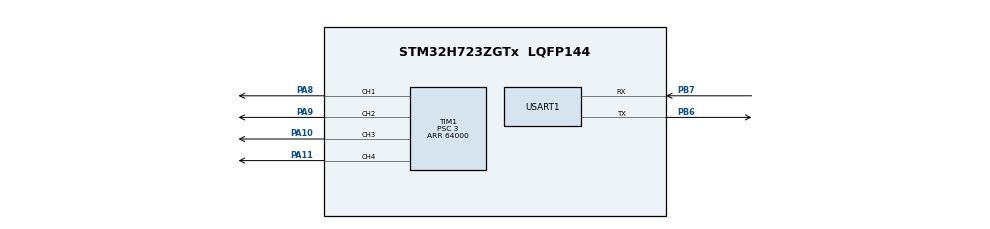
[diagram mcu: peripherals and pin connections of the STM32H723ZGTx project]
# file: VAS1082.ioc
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CORTEX_M7.CPU_DCache=Disabled
CORTEX_M7.CPU_ICache=Disabled
CORTEX_M7.default_mode_Activation=1
Mcu.Family=STM32H7
Mcu.Name=STM32H723ZGTx
Mcu.Package=LQFP144
NVIC.PriorityGroup=NVIC_PRIORITYGROUP_4
NVIC.TIM2_IRQn=true\:2\:0\:true\:false\:true\:true\:true\:true
NVIC.TIM3_IRQn=true\:1\:0\:true\:false\:true\:true\:true\:true
NVIC.TIM4_IRQn=true\:0\:0\:true\:false\:true\:true\:true\:true
NVIC.USART1_IRQn=true\:6\:0\:true\:false\:true\:true\:true\:true
PA10.Signal=S_TIM1_CH3
PA11.Signal=S_TIM1_CH4
PA13(JTMS/SWDIO).Mode=Serial_Wire
PA13(JTMS/SWDIO).Signal=DEBUG_JTMS-SWDIO
PA14(JTCK/SWCLK).Mode=Serial_Wire
PA14(JTCK/SWCLK).Signal=DEBUG_JTCK-SWCLK
PA8.Signal=S_TIM1_CH1
PA9.Signal=S_TIM1_CH2
PB6.Mode=Asynchronous
PB6.Signal=USART1_TX
PB7.Mode=Asynchronous
PB7.Signal=USART1_RX
ProjectManager.HeapSize=0x200
ProjectManager.StackSize=0x400
ProjectManager.TargetToolchain=MDK-ARM V5.32
RCC.ADCFreq_Value=129000000
RCC.APB1Freq_Value=128000000
RCC.APB2Freq_Value=128000000
RCC.APB3Freq_Value=128000000
RCC.APB4Freq_Value=128000000
RCC.CortexFreq_Value=512000000
RCC.D1PPRE=RCC_APB3_DIV2
RCC.D2PPRE1=RCC_APB1_DIV2
RCC.D2PPRE2=RCC_APB2_DIV2
RCC.D3PPRE=RCC_APB4_DIV2
RCC.DIVN1=256
RCC.DIVP1=1
RCC.HCLKFreq_Value=256000000
RCC.HPRE=RCC_HCLK_DIV2
RCC.SYSCLKFreq_VALUE=512000000
RCC.SYSCLKSource=RCC_SYSCLKSOURCE_PLLCLK
RCC.USBFreq_Value=256000000
SH.S_TIM1_CH1.0=TIM1_CH1,PWM Generation1 CH1
SH.S_TIM1_CH2.0=TIM1_CH2,PWM Generation2 CH2
SH.S_TIM1_CH3.0=TIM1_CH3,PWM Generation3 CH3
SH.S_TIM1_CH4.0=TIM1_CH4,PWM Generation4 CH4
TIM1.AutoReloadPreload=TIM_AUTORELOAD_PRELOAD_ENABLE
TIM1.Channel-PWM\ Generation1\ CH1=TIM_CHANNEL_1
TIM1.Channel-PWM\ Generation2\ CH2=TIM_CHANNEL_2
TIM1.Channel-PWM\ Generation3\ CH3=TIM_CHANNEL_3
TIM1.Channel-PWM\ Generation4\ CH4=TIM_CHANNEL_4
TIM1.Period=64000
TIM1.Prescaler=3
TIM1.Pulse-PWM\ Generation1\ CH1=0
TIM1.Pulse-PWM\ Generation2\ CH2=0
TIM1.Pulse-PWM\ Generation3\ CH3=0
TIM1.Pulse-PWM\ Generation4\ CH4=0
TIM2.AutoReloadPreload=TIM_AUTORELOAD_PRELOAD_ENABLE
TIM2.Period=2500
TIM2.Prescaler=255
TIM3.AutoReloadPreload=TIM_AUTORELOAD_PRELOAD_ENABLE
TIM3.Period=10000
TIM3.Prescaler=63
TIM4.AutoReloadPreload=TIM_AUTORELOAD_PRELOAD_ENABLE
TIM4.Period=65535
TIM4.Prescaler=255
USART1.VirtualMode-Asynchronous=VM_ASYNC
VP_TIM1_VS_ClockSourceINT.Mode=Internal
VP_TIM2_VS_ClockSourceINT.Mode=Internal
VP_TIM3_VS_ClockSourceINT.Mode=Internal
VP_TIM4_VS_ClockSourceINT.Mode=Internal
board=custom

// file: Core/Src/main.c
/* USER CODE BEGIN Header */
/**
  ******************************************************************************
  * @file           : main.c
  * @brief          : Main program body
  ******************************************************************************
  * @attention
  *
  * Copyright (c) 2025 STMicroelectronics.
  * All rights reserved.
  *
  * This software is licensed under terms that can be found in the LICENSE file
  * in the root directory of this software component.
  * If no LICENSE file comes with this software, it is provided AS-IS.
  *
  ******************************************************************************
  */
/* USER CODE END Header */
#include "main.h"
#include "tim.h"
#include "usart.h"
#include "gpio.h"

/* USER CODE BEGIN Includes */
#include "stdio.h"
/* USER CODE END Includes */

void SystemClock_Config(void);
static void MPU_Config(void);

int main(void)
{

  /* MPU Configuration--------------------------------------------------------*/
  MPU_Config();

  /* MCU Configuration--------------------------------------------------------*/

  /* Reset of all peripherals, Initializes the Flash interface and the Systick. */
  HAL_Init();

  /* Configure the system clock */
  SystemClock_Config();

  /* Initialize all configured peripherals */
  MX_GPIO_Init();
  MX_USART1_UART_Init();
  MX_TIM1_Init();
  MX_TIM2_Init();
  MX_TIM3_Init();
  MX_TIM4_Init();
  /* USER CODE BEGIN 2 */
	HAL_TIM_Base_Start_IT(&htim2);
	HAL_TIM_Base_Start_IT(&htim3);
	HAL_TIM_PWM_Start(&htim1,TIM_CHANNEL_1);
	HAL_TIM_PWM_Start(&htim1,TIM_CHANNEL_2);
	HAL_TIM_PWM_Start(&htim1,TIM_CHANNEL_3);
	HAL_TIM_PWM_Start(&htim1,TIM_CHANNEL_4);
	printf("hello\r\n");
  /* USER CODE END 2 */

  /* Infinite loop */
  while (1)
  {

    /* USER CODE BEGIN 3 */

			//HAL_Delay(100);
			//printf("END_STA:%d RxBuffer[0]:%d   RxBuffer[1]:%d   RxBuffer[2]:%d RxBuffer[3]:%d  RxBuffer[4]:%d\r\n",END_STA,RxBuffer[0],RxBuffer[1],RxBuffer[2],RxBuffer[3],RxBuffer[4]);
		Aimming();
		Freq_Sel();
		HAL_Delay(100);
	}
  /* USER CODE END 3 */
}

void SystemClock_Config(void)
{
  RCC_OscInitTypeDef RCC_OscInitStruct = {0};
  RCC_ClkInitTypeDef RCC_ClkInitStruct = {0};

  /** Supply configuration update enable
  */
  HAL_PWREx_ConfigSupply(PWR_LDO_SUPPLY);

  /** Configure the main internal regulator output voltage
  */
  __HAL_PWR_VOLTAGESCALING_CONFIG(PWR_REGULATOR_VOLTAGE_SCALE0);

  while(!__HAL_PWR_GET_FLAG(PWR_FLAG_VOSRDY)) {}

  /** Initializes the RCC Oscillators according to the specified parameters
  * in the RCC_OscInitTypeDef structure.
  */
  RCC_OscInitStruct.OscillatorType = RCC_OSCILLATORTYPE_HSI;
  RCC_OscInitStruct.HSIState = RCC_HSI_DIV1;
  RCC_OscInitStruct.HSICalibrationValue = 64;
  RCC_OscInitStruct.PLL.PLLState = RCC_PLL_ON;
  RCC_OscInitStruct.PLL.PLLSource = RCC_PLLSOURCE_HSI;
  RCC_OscInitStruct.PLL.PLLM = 32;
  RCC_OscInitStruct.PLL.PLLN = 256;
  RCC_OscInitStruct.PLL.PLLP = 1;
  RCC_OscInitStruct.PLL.PLLQ = 2;
  RCC_OscInitStruct.PLL.PLLR = 2;
  RCC_OscInitStruct.PLL.PLLRGE = RCC_PLL1VCIRANGE_1;
  RCC_OscInitStruct.PLL.PLLVCOSEL = RCC_PLL1VCOWIDE;
  RCC_OscInitStruct.PLL.PLLFRACN = 0;
  if (HAL_RCC_OscConfig(&RCC_OscInitStruct) != HAL_OK)
  {
    Error_Handler();
  }

  /** Initializes the CPU, AHB and APB buses clocks
  */
  RCC_ClkInitStruct.ClockType = RCC_CLOCKTYPE_HCLK|RCC_CLOCKTYPE_SYSCLK
                              |RCC_CLOCKTYPE_PCLK1|RCC_CLOCKTYPE_PCLK2
                              |RCC_CLOCKTYPE_D3PCLK1|RCC_CLOCKTYPE_D1PCLK1;
  RCC_ClkInitStruct.SYSCLKSource = RCC_SYSCLKSOURCE_PLLCLK;
  RCC_ClkInitStruct.SYSCLKDivider = RCC_SYSCLK_DIV1;
  RCC_ClkInitStruct.AHBCLKDivider = RCC_HCLK_DIV2;
  RCC_ClkInitStruct.APB3CLKDivider = RCC_APB3_DIV2;
  RCC_ClkInitStruct.APB1CLKDivider = RCC_APB1_DIV2;
  RCC_ClkInitStruct.APB2CLKDivider = RCC_APB2_DIV2;
  RCC_ClkInitStruct.APB4CLKDivider = RCC_APB4_DIV2;

  if (HAL_RCC_ClockConfig(&RCC_ClkInitStruct, FLASH_LATENCY_3) != HAL_OK)
  {
    Error_Handler();
  }
}

/* MPU Configuration */

void MPU_Config(void)
{
  MPU_Region_InitTypeDef MPU_InitStruct = {0};

  /* Disables the MPU */
  HAL_MPU_Disable();

  /** Initializes and configures the Region and the memory to be protected
  */
  MPU_InitStruct.Enable = MPU_REGION_ENABLE;
  MPU_InitStruct.Number = MPU_REGION_NUMBER0;
  MPU_InitStruct.BaseAddress = 0x0;
  MPU_InitStruct.Size = MPU_REGION_SIZE_4GB;
  MPU_InitStruct.SubRegionDisable = 0x87;
  MPU_InitStruct.TypeExtField = MPU_TEX_LEVEL0;
  MPU_InitStruct.AccessPermission = MPU_REGION_NO_ACCESS;
  MPU_InitStruct.DisableExec = MPU_INSTRUCTION_ACCESS_DISABLE;
  MPU_InitStruct.IsShareable = MPU_ACCESS_SHAREABLE;
  MPU_InitStruct.IsCacheable = MPU_ACCESS_NOT_CACHEABLE;
  MPU_InitStruct.IsBufferable = MPU_ACCESS_NOT_BUFFERABLE;

  HAL_MPU_ConfigRegion(&MPU_InitStruct);
  /* Enables the MPU */
  HAL_MPU_Enable(MPU_PRIVILEGED_DEFAULT);

}

void Error_Handler(void)
{
  __disable_irq();
  while (1)
  {
  }
}
